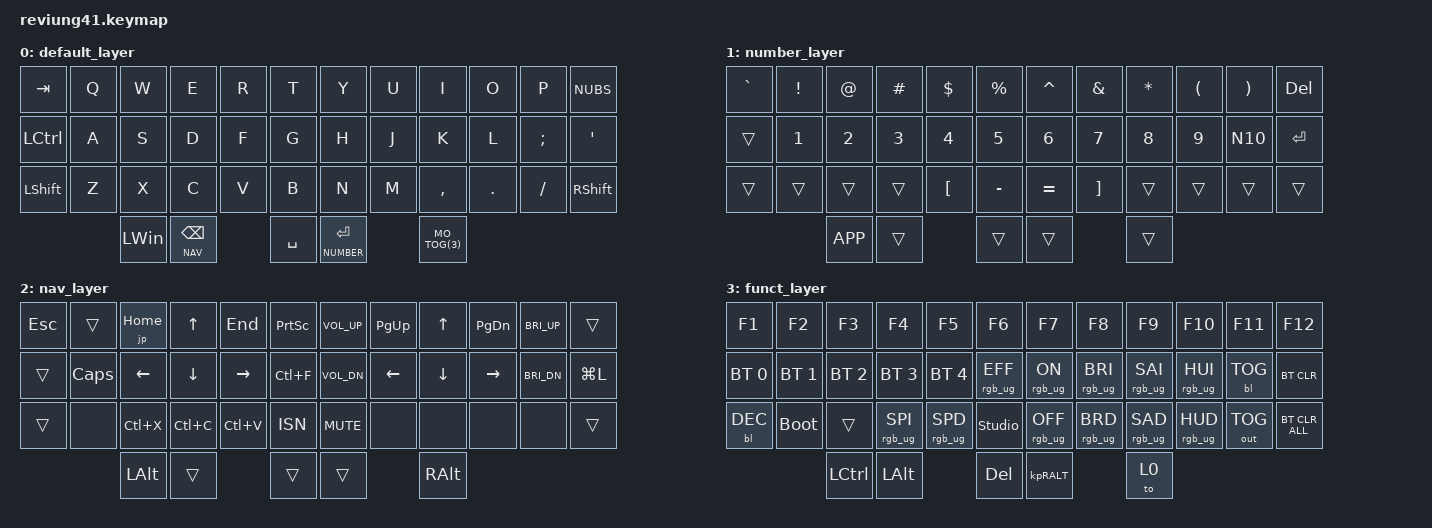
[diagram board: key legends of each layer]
/*
 * Copyright (c) 2020 The ZMK Contributors
 *
 * SPDX-License-Identifier: MIT
 */

#include <behaviors.dtsi>
#include <dt-bindings/zmk/outputs.h>
#include <dt-bindings/zmk/rgb.h>
#include <dt-bindings/zmk/bt.h>
#include <dt-bindings/zmk/keys.h>

#define DEFAULT 0
#define NUMBER  1
#define NAV     2
#define FUNCT   3
#define MO_TOG(layer) &mo_tog layer layer   // Macro to apply momentary-layer-on-hold/toggle-layer-on-tap to a specific layer
&led_strip { chain-length = <11>; };
/ {
    behaviors {
mo_tog: behavior_mo_tog {
            compatible = "zmk,behavior-hold-tap";
            label = "mo_tog";
            #binding-cells = <2>;
            flavor = "hold-preferred";
            tapping-term-ms = <200>;
            bindings = <&mo>, <&tog>;
        };
    };

    keymap {
        compatible = "zmk,keymap";

        default_layer {
            bindings = <
      &kp TAB           &kp Q       &kp W          &kp E        &kp R  &kp T                &kp Y        &kp U            &kp I         &kp O     &kp P       &kp NUBS
      &kp LCTRL         &kp A       &kp S          &kp D        &kp F  &kp G                &kp H        &kp J            &kp K         &kp L     &kp SEMI    &kp SQT
      &kp LSHIFT        &kp Z       &kp X          &kp C        &kp V  &kp B                &kp N        &kp M            &kp COMMA     &kp DOT   &kp FSLH    &kp RSHIFT
                                           &kp LWIN      &lt NAV BSPC           &kp SPACE       &lt NUMBER ENTER     MO_TOG(3)
            >;
        };

        number_layer {
            bindings = <
&kp GRAVE &kp EXCL &kp AT &kp HASH  &kp DOLLAR  &kp PERCENT             &kp CARET   &kp AMPS   &kp ASTERISK     &kp LPAR       &kp RPAR   &kp DEL
&trans    &kp N1  &kp N2  &kp N3    &kp N4      &kp N5                  &kp N6      &kp N7     &kp N8           &kp N9         &kp N10    &kp ENTER
&trans    &trans  &trans  &trans    &kp LBKT    &kp MINUS               &kp EQUAL   &kp RBKT   &trans           &trans         &trans     &trans
                                      &kp K_APP  &trans          &trans              &trans      &trans
            >;
        };

        nav_layer {
            bindings = <
&kp ESC  &trans     &jp HOME   &kp UP     &kp END    &kp PSCRN        &kp C_VOL_UP     &kp PG_UP   &kp UP     &kp PG_DN  &kp C_BRI_UP  &trans
&trans   &kp CAPS   &kp LEFT   &kp DOWN   &kp RIGHT  &kp LC(F)        &kp C_VOL_DN     &kp LEFT    &kp DOWN   &kp RIGHT  &kp C_BRI_DN  &kp LG(L)
&trans   &none      &kp LC(X)  &kp LC(C)  &kp LC(V)  &kp ISN          &kp C_MUTE       &none       &none      &none      &none         &trans
                                     &kp LALT  &trans          &trans          &trans    &kp RALT
            >;
        };

        funct_layer {
            bindings = <
&kp F1        &kp F2        &kp F3        &kp F4          &kp F5          &kp F6                      &kp F7          &kp F8          &kp F9             &kp F10          &kp F11       &kp F12
&bt BT_SEL 0  &bt BT_SEL 1  &bt BT_SEL 2  &bt BT_SEL 3    &bt BT_SEL 4    &rgb_ug RGB_EFF             &rgb_ug RGB_ON  &rgb_ug RGB_BRI &rgb_ug RGB_SAI    &rgb_ug RGB_HUI  &bl BL_TOG    &bt BT_CLR
&bl BL_DEC    &bootloader   &trans        &rgb_ug RGB_SPI &rgb_ug RGB_SPD &studio_unlock              &rgb_ug RGB_OFF &rgb_ug RGB_BRD &rgb_ug RGB_SAD    &rgb_ug RGB_HUD  &out OUT_TOG  &bt BT_CLR_ALL
                                                             &kp LCTL  &kp LALT          &kp DEL           &kpRALT        &to 0
            >;
        };
        studio1_layer {
            status = "reserved";
        };
        studio2_layer {
            status = "reserved";
        };
        studio3_layer {
            status = "reserved";
        };
        studio4_layer {
            status = "reserved";
        };
    };
};
